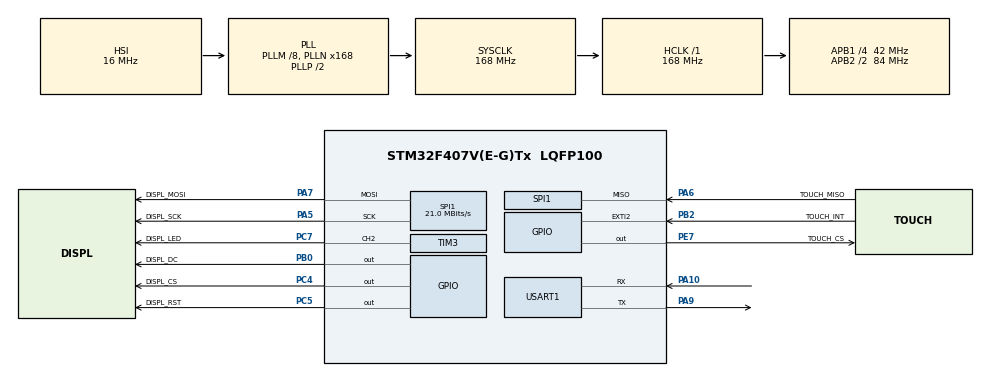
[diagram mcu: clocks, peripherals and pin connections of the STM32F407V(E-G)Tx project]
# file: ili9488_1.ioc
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Dma.Request0=SPI1_TX
Dma.SPI1_TX.0.Direction=DMA_MEMORY_TO_PERIPH
Dma.SPI1_TX.0.FIFOMode=DMA_FIFOMODE_DISABLE
Dma.SPI1_TX.0.Instance=DMA2_Stream3
Dma.SPI1_TX.0.MemDataAlignment=DMA_MDATAALIGN_BYTE
Dma.SPI1_TX.0.MemInc=DMA_MINC_ENABLE
Dma.SPI1_TX.0.Mode=DMA_NORMAL
Dma.SPI1_TX.0.PeriphDataAlignment=DMA_PDATAALIGN_BYTE
Dma.SPI1_TX.0.PeriphInc=DMA_PINC_DISABLE
Dma.SPI1_TX.0.Priority=DMA_PRIORITY_LOW
Mcu.Family=STM32F4
Mcu.Name=STM32F407V(E-G)Tx
Mcu.Package=LQFP100
NVIC.DMA2_Stream3_IRQn=true\:0\:0\:false\:false\:true\:false\:true\:true
NVIC.PriorityGroup=NVIC_PRIORITYGROUP_4
NVIC.SPI1_IRQn=true\:0\:0\:false\:false\:true\:true\:true\:true
PA10.Mode=Asynchronous
PA10.Signal=USART1_RX
PA13.Mode=Serial_Wire
PA13.Signal=SYS_JTMS-SWDIO
PA14.Mode=Serial_Wire
PA14.Signal=SYS_JTCK-SWCLK
PA5.GPIO_Label=DISPL_SCK
PA5.Mode=Full_Duplex_Master
PA5.Signal=SPI1_SCK
PA6.GPIO_Label=TOUCH_MISO
PA6.Mode=Full_Duplex_Master
PA6.Signal=SPI1_MISO
PA7.GPIO_Label=DISPL_MOSI
PA7.Mode=Full_Duplex_Master
PA7.Signal=SPI1_MOSI
PA9.Mode=Asynchronous
PA9.Signal=USART1_TX
PB0.GPIO_Label=DISPL_DC
PB0.GPIO_Speed=GPIO_SPEED_FREQ_HIGH
PB0.Signal=GPIO_Output
PB2.GPIO_Label=TOUCH_INT
PB2.GPIO_ModeDefaultEXTI=GPIO_MODE_IT_FALLING
PB2.GPIO_PuPd=GPIO_PULLUP
PB2.Signal=GPXTI2
PC4.GPIO_Label=DISPL_CS
PC4.GPIO_Speed=GPIO_SPEED_FREQ_HIGH
PC4.PinState=GPIO_PIN_SET
PC4.Signal=GPIO_Output
PC5.GPIO_Label=DISPL_RST
PC5.Signal=GPIO_Output
PC7.GPIO_Label=DISPL_LED
PC7.Signal=S_TIM3_CH2
PE7.GPIO_Label=TOUCH_CS
PE7.GPIO_Speed=GPIO_SPEED_FREQ_HIGH
PE7.PinState=GPIO_PIN_SET
PE7.Signal=GPIO_Output
PH0-OSC_IN.Mode=HSE-External-Oscillator
PH0-OSC_IN.Signal=RCC_OSC_IN
PH1-OSC_OUT.Mode=HSE-External-Oscillator
PH1-OSC_OUT.Signal=RCC_OSC_OUT
ProjectManager.HeapSize=0x200
ProjectManager.StackSize=0x400
ProjectManager.TargetToolchain=STM32CubeIDE
RCC.48MHZClocksFreq_Value=84000000
RCC.AHBFreq_Value=168000000
RCC.APB1CLKDivider=RCC_HCLK_DIV4
RCC.APB1Freq_Value=42000000
RCC.APB1TimFreq_Value=84000000
RCC.APB2CLKDivider=RCC_HCLK_DIV2
RCC.APB2Freq_Value=84000000
RCC.APB2TimFreq_Value=168000000
RCC.CortexFreq_Value=168000000
RCC.HCLKFreq_Value=168000000
RCC.HSE_VALUE=16000000
RCC.HSI_VALUE=16000000
RCC.LSE_VALUE=32768
RCC.PLLM=8
RCC.PLLN=168
RCC.SYSCLKFreq_VALUE=168000000
RCC.SYSCLKSource=RCC_SYSCLKSOURCE_PLLCLK
RCC.VCOOutputFreq_Value=336000000
SH.S_TIM3_CH2.0=TIM3_CH2,PWM Generation2 CH2
SPI1.BaudRatePrescaler=SPI_BAUDRATEPRESCALER_4
SPI1.CalculateBaudRate=21.0 MBits/s
SPI1.Direction=SPI_DIRECTION_2LINES
SPI1.Mode=SPI_MODE_MASTER
SPI1.VirtualType=VM_MASTER
STMicroelectronics.X-CUBE-TOUCHGFX.4.25.0.tgfx_buffering_strategy=Partial
STMicroelectronics.X-CUBE-TOUCHGFX.4.25.0.tgfx_custom_height=480
STMicroelectronics.X-CUBE-TOUCHGFX.4.25.0.tgfx_custom_width=320
STMicroelectronics.X-CUBE-TOUCHGFX.4.25.0_IsPackSelfContextualization=true
TIM3.Channel-PWM\ Generation2\ CH2=TIM_CHANNEL_2
TIM3.Period=100
TIM3.Prescaler=10000
USART1.VirtualMode=VM_ASYNC
VP_CRC_VS_CRC.Mode=CRC_Activate
board=custom

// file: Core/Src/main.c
/* USER CODE BEGIN Header */
/**
  ******************************************************************************
  * @file           : main.c
  * @brief          : Main program body
  ******************************************************************************
  * @attention
  *
  * Copyright (c) 2025 STMicroelectronics.
  * All rights reserved.
  *
  * This software is licensed under terms that can be found in the LICENSE file
  * in the root directory of this software component.
  * If no LICENSE file comes with this software, it is provided AS-IS.
  *
  ******************************************************************************
  */
/* USER CODE END Header */
#include "main.h"

CRC_HandleTypeDef hcrc;

SPI_HandleTypeDef hspi1;
DMA_HandleTypeDef hdma_spi1_tx;

TIM_HandleTypeDef htim3;

UART_HandleTypeDef huart1;

void SystemClock_Config(void);
static void MX_GPIO_Init(void);
static void MX_DMA_Init(void);
static void MX_USART1_UART_Init(void);
static void MX_SPI1_Init(void);
static void MX_CRC_Init(void);
static void MX_TIM3_Init(void);

/* USER CODE BEGIN 0 */
void show_uart( char *ss)
{
  char test[50];
  int len;
  strcpy(test, ss);
  strcat(test, "\r\n");
  len = strlen (test);
  HAL_UART_Transmit(&huart1, (uint8_t *) test, len, HAL_MAX_DELAY);
}
/* USER CODE END 0 */

int main(void)
{

  /* MCU Configuration--------------------------------------------------------*/

  /* Reset of all peripherals, Initializes the Flash interface and the Systick. */
  HAL_Init();

  /* Configure the system clock */
  SystemClock_Config();

  /* Initialize all configured peripherals */
  MX_GPIO_Init();
  MX_DMA_Init();
  MX_USART1_UART_Init();
  MX_SPI1_Init();
  MX_CRC_Init();
  MX_TIM3_Init();
  /* USER CODE BEGIN 2 */
  show_uart("start");
  Displ_Init(Displ_Orientat_270);
  Displ_CLS(BLACK);
 // Displ_drawCircle(0,0,100,RED);
  //Displ_Line(0,1OO,100,100,BLUE);
//  Displ_WChar(100,100,"HELLO",Font20,20,RED,WHITE);
 // Displ_CString(0,0,0,0, "RESULTS", Font24, 1, WHITE,BLUE);
  Displ_PerfTest();
  /* USER CODE END 2 */

  /* Infinite loop */
  while (1)
  {

  }
}

void SystemClock_Config(void)
{
  RCC_OscInitTypeDef RCC_OscInitStruct = {0};
  RCC_ClkInitTypeDef RCC_ClkInitStruct = {0};

  /** Configure the main internal regulator output voltage
  */
  __HAL_RCC_PWR_CLK_ENABLE();
  __HAL_PWR_VOLTAGESCALING_CONFIG(PWR_REGULATOR_VOLTAGE_SCALE1);

  /** Initializes the RCC Oscillators according to the specified parameters
  * in the RCC_OscInitTypeDef structure.
  */
  RCC_OscInitStruct.OscillatorType = RCC_OSCILLATORTYPE_HSI;
  RCC_OscInitStruct.HSIState = RCC_HSI_ON;
  RCC_OscInitStruct.HSICalibrationValue = RCC_HSICALIBRATION_DEFAULT;
  RCC_OscInitStruct.PLL.PLLState = RCC_PLL_ON;
  RCC_OscInitStruct.PLL.PLLSource = RCC_PLLSOURCE_HSI;
  RCC_OscInitStruct.PLL.PLLM = 8;
  RCC_OscInitStruct.PLL.PLLN = 168;
  RCC_OscInitStruct.PLL.PLLP = RCC_PLLP_DIV2;
  RCC_OscInitStruct.PLL.PLLQ = 4;
  if (HAL_RCC_OscConfig(&RCC_OscInitStruct) != HAL_OK)
  {
    Error_Handler();
  }

  /** Initializes the CPU, AHB and APB buses clocks
  */
  RCC_ClkInitStruct.ClockType = RCC_CLOCKTYPE_HCLK|RCC_CLOCKTYPE_SYSCLK
                              |RCC_CLOCKTYPE_PCLK1|RCC_CLOCKTYPE_PCLK2;
  RCC_ClkInitStruct.SYSCLKSource = RCC_SYSCLKSOURCE_PLLCLK;
  RCC_ClkInitStruct.AHBCLKDivider = RCC_SYSCLK_DIV1;
  RCC_ClkInitStruct.APB1CLKDivider = RCC_HCLK_DIV4;
  RCC_ClkInitStruct.APB2CLKDivider = RCC_HCLK_DIV2;

  if (HAL_RCC_ClockConfig(&RCC_ClkInitStruct, FLASH_LATENCY_5) != HAL_OK)
  {
    Error_Handler();
  }
}

static void MX_CRC_Init(void)
{

  hcrc.Instance = CRC;
  if (HAL_CRC_Init(&hcrc) != HAL_OK)
  {
    Error_Handler();
  }

}

static void MX_SPI1_Init(void)
{

  /* SPI1 parameter configuration*/
  hspi1.Instance = SPI1;
  hspi1.Init.Mode = SPI_MODE_MASTER;
  hspi1.Init.Direction = SPI_DIRECTION_2LINES;
  hspi1.Init.DataSize = SPI_DATASIZE_8BIT;
  hspi1.Init.CLKPolarity = SPI_POLARITY_LOW;
  hspi1.Init.CLKPhase = SPI_PHASE_1EDGE;
  hspi1.Init.NSS = SPI_NSS_SOFT;
  hspi1.Init.BaudRatePrescaler = SPI_BAUDRATEPRESCALER_4;
  hspi1.Init.FirstBit = SPI_FIRSTBIT_MSB;
  hspi1.Init.TIMode = SPI_TIMODE_DISABLE;
  hspi1.Init.CRCCalculation = SPI_CRCCALCULATION_DISABLE;
  hspi1.Init.CRCPolynomial = 10;
  if (HAL_SPI_Init(&hspi1) != HAL_OK)
  {
    Error_Handler();
  }

}

static void MX_TIM3_Init(void)
{

  TIM_MasterConfigTypeDef sMasterConfig = {0};
  TIM_OC_InitTypeDef sConfigOC = {0};

  htim3.Instance = TIM3;
  htim3.Init.Prescaler = 10000;
  htim3.Init.CounterMode = TIM_COUNTERMODE_UP;
  htim3.Init.Period = 100;
  htim3.Init.ClockDivision = TIM_CLOCKDIVISION_DIV1;
  htim3.Init.AutoReloadPreload = TIM_AUTORELOAD_PRELOAD_DISABLE;
  if (HAL_TIM_PWM_Init(&htim3) != HAL_OK)
  {
    Error_Handler();
  }
  sMasterConfig.MasterOutputTrigger = TIM_TRGO_RESET;
  sMasterConfig.MasterSlaveMode = TIM_MASTERSLAVEMODE_DISABLE;
  if (HAL_TIMEx_MasterConfigSynchronization(&htim3, &sMasterConfig) != HAL_OK)
  {
    Error_Handler();
  }
  sConfigOC.OCMode = TIM_OCMODE_PWM1;
  sConfigOC.Pulse = 0;
  sConfigOC.OCPolarity = TIM_OCPOLARITY_HIGH;
  sConfigOC.OCFastMode = TIM_OCFAST_DISABLE;
  if (HAL_TIM_PWM_ConfigChannel(&htim3, &sConfigOC, TIM_CHANNEL_2) != HAL_OK)
  {
    Error_Handler();
  }
  HAL_TIM_MspPostInit(&htim3);

}

static void MX_USART1_UART_Init(void)
{

  huart1.Instance = USART1;
  huart1.Init.BaudRate = 115200;
  huart1.Init.WordLength = UART_WORDLENGTH_8B;
  huart1.Init.StopBits = UART_STOPBITS_1;
  huart1.Init.Parity = UART_PARITY_NONE;
  huart1.Init.Mode = UART_MODE_TX_RX;
  huart1.Init.HwFlowCtl = UART_HWCONTROL_NONE;
  huart1.Init.OverSampling = UART_OVERSAMPLING_16;
  if (HAL_UART_Init(&huart1) != HAL_OK)
  {
    Error_Handler();
  }

}

static void MX_DMA_Init(void)
{

  /* DMA controller clock enable */
  __HAL_RCC_DMA2_CLK_ENABLE();

  /* DMA interrupt init */
  /* DMA2_Stream3_IRQn interrupt configuration */
  HAL_NVIC_SetPriority(DMA2_Stream3_IRQn, 0, 0);
  HAL_NVIC_EnableIRQ(DMA2_Stream3_IRQn);

}

static void MX_GPIO_Init(void)
{
  GPIO_InitTypeDef GPIO_InitStruct = {0};

  /* GPIO Ports Clock Enable */
  __HAL_RCC_GPIOH_CLK_ENABLE();
  __HAL_RCC_GPIOA_CLK_ENABLE();
  __HAL_RCC_GPIOC_CLK_ENABLE();
  __HAL_RCC_GPIOB_CLK_ENABLE();
  __HAL_RCC_GPIOE_CLK_ENABLE();

  /*Configure GPIO pin Output Level */
  HAL_GPIO_WritePin(DISPL_CS_GPIO_Port, DISPL_CS_Pin, GPIO_PIN_SET);

  /*Configure GPIO pin Output Level */
  HAL_GPIO_WritePin(DISPL_RST_GPIO_Port, DISPL_RST_Pin, GPIO_PIN_RESET);

  /*Configure GPIO pin Output Level */
  HAL_GPIO_WritePin(DISPL_DC_GPIO_Port, DISPL_DC_Pin, GPIO_PIN_RESET);

  /*Configure GPIO pin Output Level */
  HAL_GPIO_WritePin(TOUCH_CS_GPIO_Port, TOUCH_CS_Pin, GPIO_PIN_SET);

  /*Configure GPIO pin : DISPL_CS_Pin */
  GPIO_InitStruct.Pin = DISPL_CS_Pin;
  GPIO_InitStruct.Mode = GPIO_MODE_OUTPUT_PP;
  GPIO_InitStruct.Pull = GPIO_NOPULL;
  GPIO_InitStruct.Speed = GPIO_SPEED_FREQ_HIGH;
  HAL_GPIO_Init(DISPL_CS_GPIO_Port, &GPIO_InitStruct);

  /*Configure GPIO pin : DISPL_RST_Pin */
  GPIO_InitStruct.Pin = DISPL_RST_Pin;
  GPIO_InitStruct.Mode = GPIO_MODE_OUTPUT_PP;
  GPIO_InitStruct.Pull = GPIO_NOPULL;
  GPIO_InitStruct.Speed = GPIO_SPEED_FREQ_LOW;
  HAL_GPIO_Init(DISPL_RST_GPIO_Port, &GPIO_InitStruct);

  /*Configure GPIO pin : DISPL_DC_Pin */
  GPIO_InitStruct.Pin = DISPL_DC_Pin;
  GPIO_InitStruct.Mode = GPIO_MODE_OUTPUT_PP;
  GPIO_InitStruct.Pull = GPIO_NOPULL;
  GPIO_InitStruct.Speed = GPIO_SPEED_FREQ_HIGH;
  HAL_GPIO_Init(DISPL_DC_GPIO_Port, &GPIO_InitStruct);

  /*Configure GPIO pin : TOUCH_INT_Pin */
  GPIO_InitStruct.Pin = TOUCH_INT_Pin;
  GPIO_InitStruct.Mode = GPIO_MODE_IT_FALLING;
  GPIO_InitStruct.Pull = GPIO_PULLUP;
  HAL_GPIO_Init(TOUCH_INT_GPIO_Port, &GPIO_InitStruct);

  /*Configure GPIO pin : TOUCH_CS_Pin */
  GPIO_InitStruct.Pin = TOUCH_CS_Pin;
  GPIO_InitStruct.Mode = GPIO_MODE_OUTPUT_PP;
  GPIO_InitStruct.Pull = GPIO_NOPULL;
  GPIO_InitStruct.Speed = GPIO_SPEED_FREQ_HIGH;
  HAL_GPIO_Init(TOUCH_CS_GPIO_Port, &GPIO_InitStruct);

}

void Error_Handler(void)
{
  __disable_irq();
  while (1)
  {
  }
}
